# RL6955_IP_SVD register map
Vendor: Realtek
Registers are 32-bit, read-write, reset 0x0 unless marked. A register's access mark holds for its fields unless they carry their own. Offsets are from the block's base; [hi:lo] are bit positions; {n}, {i} and the like mark numbered series.

## RSIP_REG
Base 0x41894000
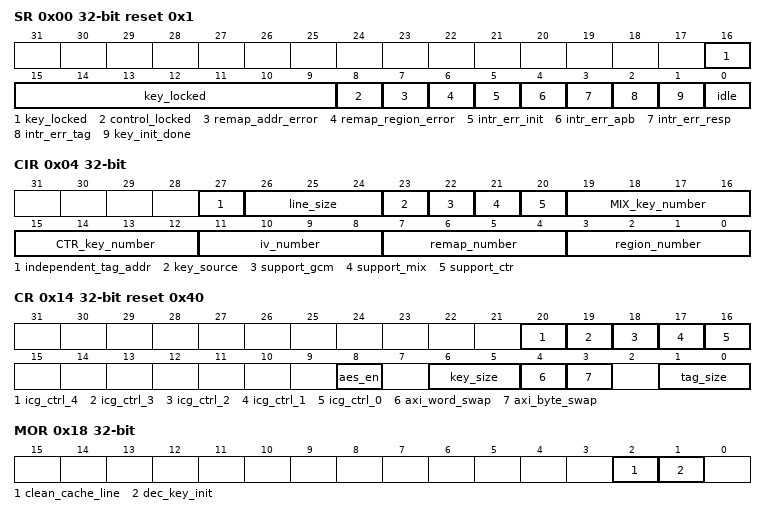
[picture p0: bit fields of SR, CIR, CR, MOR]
0x00 SR ro reset 0x1 — Status Register
  [16:9] key_locked — Indicates whether the keyx is locked. If it is locked, keyx cannot be written or read
  [8] control_locked — Indicates whether the setting is locked. If it is locked, only Clr_intr and Maintenance registers can be set
  [7] remap_addr_error — Indicates the address after adding offset size cross 256MB boundaries
  [6] remap_region_error — Indicates the read address hits multiple remapping region.
  [5] intr_err_init — Indicates the transaction was received before the key initialization is completed.
  [4] intr_err_apb — Indicates whether the setting configuration failed. When a transaction is in progress, all settings except clear interruption are invalid.
  [3] intr_err_resp — Indicates a the error response is received from slave.
  [2] intr_err_tag — Indicates a GCM tag mismatch error occurred.
  [1] key_init_done — Indicates whether the initialization of the key is completed. Only used in MIX mode.
  [0] idle — Indicates whether there is any outstanding transaction.
0x04 CIR ro — Component Identification Register
  [27] independent_tag_addr — Indicates the storage location of the tag 0: consecutive space - interleaved with each data blocks1: separate space from data - use another base address
  [26:24] line_size — Cache line size 0: 16B = 1 AES block 1: 32B = 2 AES blocks 2: 64B = 4 AES blocks 3: 128B = 8 AES blocks Indicates how many 128-bit blocks are used to calculate the tag cache line size (Byte) = 16 * 2BLOCK_SIZE
  [23] key_source — Indicates the key source 0: from dedicated key port 1: from APB register
  [22] support_gcm — Indicate whether GCM mode is supported.
  [21] support_mix — Indicate whether MIX mode is supported.
  [20] support_ctr — Indicate whether CTR mode is supported.
  [19:16] MIX_key_number — Number of supported MIX key registers, valid when support_mix is 1
  [15:12] CTR_key_number — Number of supported CTR key registers, valid when support_ctr or support_gcm is 1
  [11:8] iv_number — Number of supported IVs registers
  [7:4] remap_number — Number of supported remap regions
  [3:0] region_number — Number of supported decryption regions
0x08 EALR ro — Error Address Log Register
  [31:0] error_address — Recorded address when GCM Tag mismatch error or receiving an error response.
0x10 ICR wo — Interrupt Clear Register
  [0] clr_intr — Interrupt clear.It has to write 1'b1 to this register every time when the error exception occurs.
0x14 CR reset 0x40 — Control Register
  [20] icg_ctrl_4 — Disable key-reg auto clock gating
  [19] icg_ctrl_3 — Disable apb-ctrl auto clock gating
  [18] icg_ctrl_2 — Disable aes-engine auto clock gating
  [17] icg_ctrl_1 — Disable fetch-unit auto clock gating
  [16] icg_ctrl_0 — Disable line-buffer auto clock gating
  [8] aes_en — Determine whether to enable the AES engine 0: disable decryption engine (expect remapping function) 1: enable decryption engine and line buffer
  [6:5] key_size — Determine the size of KEY 0: 128 bits 1: 192 bits 2: 256 bits
  [4] axi_word_swap — Determine the endian of ciphertext in slave memory. If set to 1, can swap word order.
  [3] axi_byte_swap — Determine the endian of ciphertext in slave memory. If set to 1, can swap byte order.
  [1:0] tag_size — Tag size. The size of the tag will affect the length of each tag command. 0: 32 bits 1: 64 bits 2: 128bits
0x18 MOR wo — Maintenance Operation Register
  [2] clean_cache_line — Manually clear the line buffer. Write 1 to clear all after flash data update.
  [1] dec_key_init — Only used in MIX mode. Whenever the key is changed, write 1 to this bit to initialize the decryption key. When keys are update by external port, sec engine will trigger this bit automatically. The status of completion can be determined by reading bit 1 of the status register.
0x1C LR wo — Lock Register
  [7:0] lock_control — When set DC to this field, all registers except Clr_intr, Maintenance and keys are not allowed to be written. Once the lock is set, the way to unlock is reset the flash SEC engine. If SW wants to modified the setting of control registers, it should keep this lock unset.
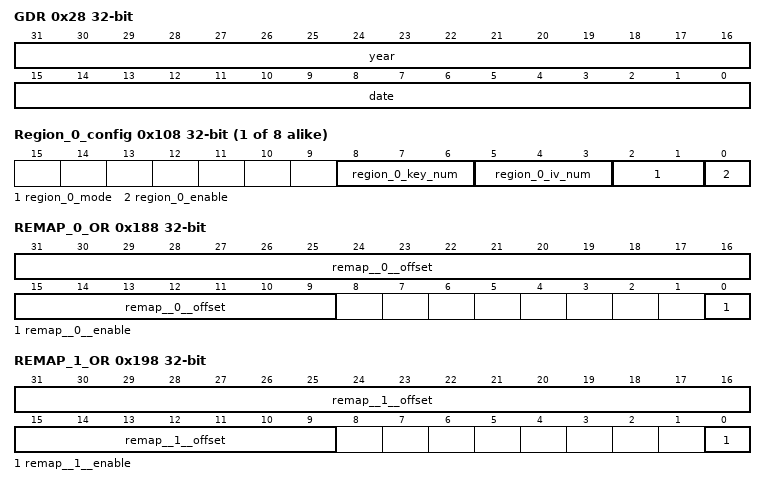
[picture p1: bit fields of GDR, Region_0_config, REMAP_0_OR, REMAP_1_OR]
0x28 GDR ro — Gen Date Register
  [31:16] year — Year of code generation
  [15:0] date — Date of code generation
0x2C VR ro — Version Register
  [31:0] version — Version of code generation
{0x30+4i} Lock_key{i} wo (i=0..7)
  [7:0] lock_key{i} — When set DC to this field, key_x are not allowed to be written or read. Once the lock is set, the way to unlock is reset the flash SEC engine. If SW wants to modified the key registers, it should keep this lock unset.
{0x60+8i} IV_{i}_L (i=0..7) — IV {i} Bit [95:64]
  [31:0] iv__{i}__low — Fixed field of IV value. iv_x [95:64] If LINE_SIZE = 32B, IV = iv_x_high32 || iv_x_low32 || (address >> (4+log2(LINE_SIZE/16)))32 || (2)32 If LINE_SIZE > 32B, IV = iv_x_high32 || iv_x_low32 || (address >> (4+log2(LINE_SIZE/16)))32 || (address[4+log2(LINE_SIZE/16)-1:4] + 2)32
{0x64+8i} IV_{i}_H (i=0..7) — IV {i} Bit [127:96]
  [31:0] iv__{i}__high — Fixed field of IV value. iv__{i}_ [127:96] If LINE_SIZE = 32B, IV = iv_x_high32 || iv_x_low32 || (address >> (4+log2(LINE_SIZE/16)))32 || (2)32 If LINE_SIZE > 32B, IV = iv_x_high32 || iv_x_low32 || (address >> (4+log2(LINE_SIZE/16)))32 || (address[4+log2(LINE_SIZE/16)-1:4] + 2)32
{0x100+0x10*i} Region_{i}_base (i=0..7) — Region {i} base address register
  [31:5] region_{i}_base — Region {i} base address register.
{0x104+0x10*i} Region_{i}_end (i=0..7) — Region {i} end address register
  [31:5] region_{i}_end — Region {i} end address register.
{0x108+0x10*i} Region_{i}_config (i=0..7) — Region {i} setting register
  [8:6] region_{i}_key_num — Key used in region {i} Apply which key reigster to this region Number corresponds to key register
  [5:3] region_{i}_iv_num — IV used in region {i} Apply which IV reigster to this region Number corresponds to IV register
  [2:1] region_{i}_mode — Mode used in region {i} 2'b00: GCM mode 2'b01: CTR mode 2'b10: MIX mode 2'b11: Reserved
  [0] region_{i}_enable — Enable region x setting
{0x10C+0x10*i} Region_{i}_tag_base (i=0..7) — Region {i} GCM tag base address register
  [31:0] region_{i}_tag_base_addr — Region {i} GCM tag base address
0x180 REMAP_0_BAR — REMAP 0 region base address register
  [31:9] remap_base__0__addr — Remap region x base address [27:5] Region_Base_Addr = {flash_base[31:28], remap_base_x_addr, {5{1'b0}} } The region address is configurable, and not cross 256KB
{0x184+0xC*i} REMAP_{i}_EAR (i=0..7) — REMAP {i} region end address register
  [31:9] remap_end__{i}__addr — Remap region _{i}_ end address [27:5] Region_End_Addr = {flash_base[31:28], remap_end__{i}__addr, {5{1'b0}} } The region address is configurable, and not cross 256KB
0x188 REMAP_0_OR
  [31:9] remap__0__offset — Remap region _0_ offset [27:5] Region_Offset = {4'b0,remap__0__offset, {5{1'b0}} }The output address is "Access address - Region_Base_Addr + Region_Offset"
  [0] remap__0__enable — Remap region _0_ enable
0x18C REMAP_1_BAR — REMAP 1 region base address register
  [31:9] remap_base__1__addr — Remap region x base address [27:5] Region_Base_Addr = {flash_base[31:28], remap_base_x_addr, {5{1'b0}} } The region address is configurable, and not cross 256KB
0x198 REMAP_1_OR
  [31:9] remap__1__offset — Remap region _1_ offset [27:5] Region_Offset = {4'b0,remap__1__offset, {5{1'b0}} }The output address is "Access address - Region_Base_Addr + Region_Offset"
  [0] remap__1__enable — Remap region _1_ enable
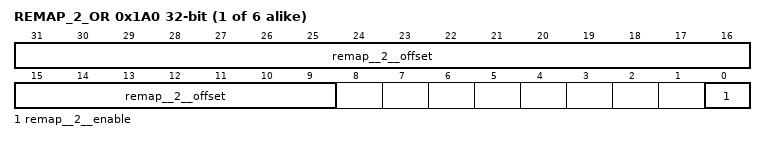
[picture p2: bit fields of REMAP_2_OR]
{0x188+0xC*i} REMAP_{i}_OR (i=2..7)
  [31:9] remap__{i}__offset — Remap region _{i}_ offset [27:5] Region_Offset = {4'b0,remap__{i}__offset, {5{1'b0}} }The output address is "Access address - Region_Base_Addr + Region_Offset"
  [0] remap__{i}__enable — Remap region _{i}_ enable
{0x180+0xC*i} REMAP_{i}_BAR (i=3..7) — REMAP {i} region base address register
  [31:9] remap_base__{i}__addr — Remap region x base address [27:5] Region_Base_Addr = {flash_base[31:28], remap_base_x_addr, {5{1'b0}} } The region address is configurable, and not cross 256KB
{0x200+0x20*i} Key{i}_0 (i=0..7) — Key{i} [31:0]
  [31:0] key{i}_0 — Key{i} register [31:0] CTR of MIX, GCM, CTR mode using the key
{0x204+0x20*i} Key{i}_1 (i=0..7) — Key{i} [63:32]
  [31:0] key{i}_1 — Key{i} register [63:32] CTR of MIX, GCM, CTR mode using the key
{0x208+0x20*i} Key{i}_2 (i=0..7) — Key{i} [95:64]
  [31:0] key{i}_2 — Key{i} register [95:64] CTR of MIX, GCM, CTR mode using the key
{0x20C+0x20*i} Key{i}_3 (i=0..7) — Key{i} [127:96]
  [31:0] key{i}_3 — Key{i} register [127:96] CTR of MIX, GCM, CTR mode using the key
{0x210+0x20*i} Key{i}_4 (i=0..7) — Key{i} [159:128]
  [31:0] key{i}_4 — Key{i} register 159:128] CTR of MIX, GCM, CTR mode using the key
{0x214+0x20*i} Key{i}_5 (i=0..7) — Key{i} [191:160]
  [31:0] key{i}_5 — Key{i} register [191:160] CTR of MIX, GCM, CTR mode using the key
{0x218+0x20*i} Key{i}_6 (i=0..7) — Key{i} [223:192]
  [31:0] key{i}_6 — Key{i} register [223:192] CTR of MIX, GCM, CTR mode using the key
{0x21C+0x20*i} Key{i}_7 (i=0..7) — Key{i} [255:224]
  [31:0] key{i}_7 — Key{i} register [255:224] CTR of MIX, GCM, CTR mode using the key
